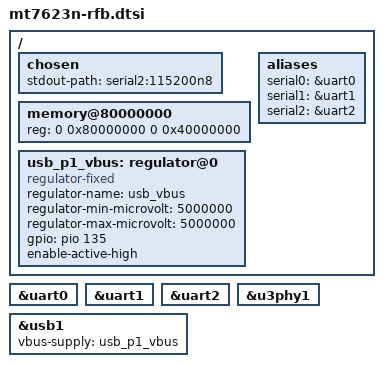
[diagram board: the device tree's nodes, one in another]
/*
 * Copyright (c) 2016 MediaTek Inc.
 * Author: John Crispin <blogic@openwrt.org>
 *
 * This program is free software; you can redistribute it and/or modify
 * it under the terms of the GNU General Public License version 2 as
 * published by the Free Software Foundation.
 *
 * This program is distributed in the hope that it will be useful,
 * but WITHOUT ANY WARRANTY; without even the implied warranty of
 * MERCHANTABILITY or FITNESS FOR A PARTICULAR PURPOSE.  See the
 * GNU General Public License for more details.
 */

#include "mt7623-mt6323.dtsi"

/ {
	chosen {
		stdout-path = "serial2:115200n8";
	};

	memory@80000000 {
		reg = <0 0x80000000 0 0x40000000>;
	};

	aliases {
		serial0 = &uart0;
		serial1 = &uart1;
		serial2 = &uart2;
	};

	usb_p1_vbus: regulator@0 {
		compatible = "regulator-fixed";
		regulator-name = "usb_vbus";
		regulator-min-microvolt = <5000000>;
		regulator-max-microvolt = <5000000>;
		gpio = <&pio 135 GPIO_ACTIVE_HIGH>;
		enable-active-high;
	};
};

&uart0 {
	status = "okay";
};

&uart1 {
	status = "okay";
};

&uart2 {
	status = "okay";
};

&usb1 {
	vbus-supply = <&usb_p1_vbus>;
	status = "okay";
};

&u3phy1 {
	status = "okay";
};
